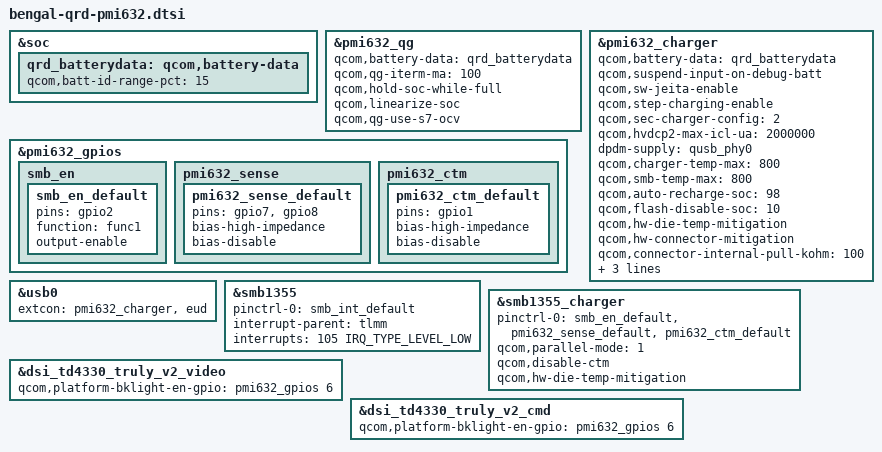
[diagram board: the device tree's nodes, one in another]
#include "bengal-pmi632.dtsi"

&soc {
	qrd_batterydata: qcom,battery-data {
		qcom,batt-id-range-pct = <15>;
		#include "qg-batterydata-atl466271_3300mAh.dtsi"
	};
};

&pmi632_qg {
	qcom,battery-data = <&qrd_batterydata>;
	qcom,qg-iterm-ma = <100>;
	qcom,hold-soc-while-full;
	qcom,linearize-soc;
	qcom,qg-use-s7-ocv;
};

&pmi632_charger {
	qcom,battery-data = <&qrd_batterydata>;
	qcom,suspend-input-on-debug-batt;
	qcom,sw-jeita-enable;
	qcom,step-charging-enable;
	/* SMB1355 only */
	qcom,sec-charger-config = <2>;
	qcom,hvdcp2-max-icl-ua = <2000000>;
	dpdm-supply = <&qusb_phy0>;
	qcom,charger-temp-max = <800>;
	qcom,smb-temp-max = <800>;
	qcom,auto-recharge-soc = <98>;
	qcom,flash-disable-soc = <10>;
	qcom,hw-die-temp-mitigation;
	qcom,hw-connector-mitigation;
	qcom,connector-internal-pull-kohm = <100>;
	qcom,float-option = <1>;
	qcom,thermal-mitigation = <4200000 3500000 3000000
			2500000 2000000 1500000 1000000 500000>;
};

&pmi632_gpios {
	smb_en {
		smb_en_default: smb_en_default {
			pins = "gpio2";
			function = "func1";
			output-enable;
		};
	};

	pmi632_sense {
		/* GPIO 7 and 8 are external-sense pins for PMI632 */
		pmi632_sense_default: pmi632_sense_default {
			pins = "gpio7", "gpio8";
			bias-high-impedance;	/* disable the GPIO */
			bias-disable;		/* no-pull */
		};
	};

	pmi632_ctm {
		/* Disable GPIO1 for h/w base mitigation */
		pmi632_ctm_default: pmi632_ctm_default {
			pins = "gpio1";
			bias-high-impedance;	/* disable the GPIO */
			bias-disable;		/* no-pull */
		};
	};
};

&usb0 {
	extcon = <&pmi632_charger>, <&eud>;
};

&smb1355 {
	pinctrl-names = "default";
	pinctrl-0 = <&smb_int_default>;
	interrupt-parent = <&tlmm>;
	interrupts = <105 IRQ_TYPE_LEVEL_LOW>;
	status = "ok";
};

&smb1355_charger {
	pinctrl-names = "default";
	pinctrl-0 = <&smb_en_default &pmi632_sense_default &pmi632_ctm_default>;
	qcom,parallel-mode = <1>;
	qcom,disable-ctm;
	qcom,hw-die-temp-mitigation;
	status = "ok";
};

&dsi_td4330_truly_v2_video {
	qcom,platform-bklight-en-gpio = <&pmi632_gpios 6 0>;
};

&dsi_td4330_truly_v2_cmd {
	qcom,platform-bklight-en-gpio = <&pmi632_gpios 6 0>;
};
